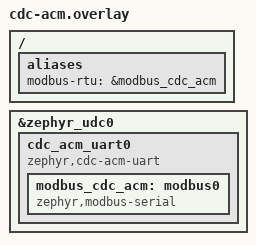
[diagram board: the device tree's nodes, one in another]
/*
 * Copyright (c) 2022 Nordic Semiconductor ASA
 *
 * SPDX-License-Identifier: Apache-2.0
 */


&zephyr_udc0 {
	cdc_acm_uart0: cdc_acm_uart0 {
		compatible = "zephyr,cdc-acm-uart";
        status = "okay";

		modbus_cdc_acm: modbus0 {
			compatible = "zephyr,modbus-serial";
			status = "okay";
		};
	};
};

/ {
       aliases {
              modbus-rtu = &modbus_cdc_acm;
       };
};
